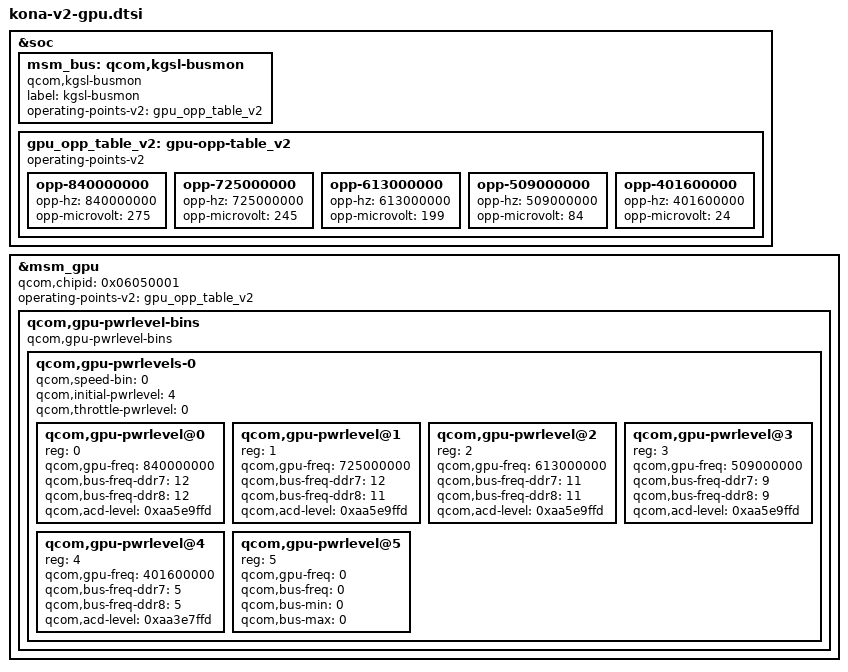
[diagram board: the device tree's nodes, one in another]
&soc {
	msm_bus: qcom,kgsl-busmon {
		label = "kgsl-busmon";
		compatible = "qcom,kgsl-busmon";
		operating-points-v2 = <&gpu_opp_table_v2>;
	};

	gpu_opp_table_v2: gpu-opp-table_v2 {
		compatible = "operating-points-v2";


		opp-840000000 {
			opp-hz = /bits/ 64 <840000000>;
                       opp-microvolt = <275>;
		};

		opp-725000000 {
			opp-hz = /bits/ 64 <725000000>;
                       opp-microvolt = <245>;
		};

		opp-613000000 {
			opp-hz = /bits/ 64 <613000000>;
                       opp-microvolt = <199>;
		};

		opp-509000000 {
			opp-hz = /bits/ 64 <509000000>;
                       opp-microvolt = <84>;
		};
		
		opp-401600000 {
			opp-hz = /bits/ 64 <401600000>;
                       opp-microvolt = <24>;
		};
	};
};

&msm_gpu {
	qcom,chipid = <0x06050001>;

	/* GPU OPP data */
	operating-points-v2 = <&gpu_opp_table_v2>;

	/delete-property/qcom,initial-pwrlevel;
	/delete-node/qcom,gpu-pwrlevels;

	/* Power levels bins */
	qcom,gpu-pwrlevel-bins {
		compatible="qcom,gpu-pwrlevel-bins";
		#address-cells = <1>;
		#size-cells = <0>;

		qcom,gpu-pwrlevels-0 {
			#address-cells = <1>;
			#size-cells = <0>;
			qcom,speed-bin = <0>;
			qcom,initial-pwrlevel = <4>;
			qcom,throttle-pwrlevel = <0>;


                        qcom,gpu-pwrlevel@0 {
                                reg = <0>;
                                qcom,gpu-freq = <840000000>;
                                
                                qcom,bus-freq-ddr7 = <12>;                         
                                qcom,bus-freq-ddr8 = <12>;
                                
                                qcom,acd-level = <0xaa5e9ffd>;
                        };

                        qcom,gpu-pwrlevel@1 {
                                reg = <1>;
                                qcom,gpu-freq = <725000000>;
                                
                                qcom,bus-freq-ddr7 = <12>;                       
                                qcom,bus-freq-ddr8 = <11>;
                                
                                qcom,acd-level = <0xaa5e9ffd>;
                        };
                        
                        qcom,gpu-pwrlevel@2 {
                                reg = <2>;
                                qcom,gpu-freq = <613000000>;
                                
                                qcom,bus-freq-ddr7 = <11>; 
                                qcom,bus-freq-ddr8 = <11>;
                                
                                qcom,acd-level = <0xaa5e9ffd>;
                        };
                        
                        qcom,gpu-pwrlevel@3 {
                                reg = <3>;
                                qcom,gpu-freq = <509000000>;
                                
                                qcom,bus-freq-ddr7 = <9>;                             
                                qcom,bus-freq-ddr8 = <9>;
                                
                                qcom,acd-level = <0xaa5e9ffd>;
                        };

			qcom,gpu-pwrlevel@4 {
				reg = <4>;
				qcom,gpu-freq = <401600000>;
					
				qcom,bus-freq-ddr7 = <5>;
				qcom,bus-freq-ddr8 = <5>;
				
				qcom,acd-level = <0xaa3e7ffd>;
			};

			qcom,gpu-pwrlevel@5 {
				reg = <5>;
				qcom,gpu-freq = <0>;
				qcom,bus-freq = <0>;
				qcom,bus-min = <0>;
				qcom,bus-max = <0>;
			};
		};
	};
};
